# MSS_VIM register map
Vendor: Texas Instruments
Peripheral module from a debugger description file (folder radar).
Registers are 32-bit, read-write, no defined reset value unless marked. A register's access mark holds for its fields unless they carry their own. Offsets are as the file gives them; lines under a group give offsets from that group; [hi:lo] are bit positions; {n}, {i} and the like mark numbered series; 'fields as' and 'values as' point back to an identical list; <NAME> marks a mode.

## VIM
0x00 IRQIVEC
  [7:0] IRQIVEC — IRQIVEC Index vector. User and privilege mode read: The least significant bits represent the index of the IRQ pending interrupt with the highest precedence. When no interrupts are pending, IRQIVEC field will read 0x00. User and privilege mode write: Writes have no effect. User and privilege mode read: Clears the internal PULSE_HOLD flag corresponding to the vector number that is read out. Refer to Figure 1–9. for details about PULSE_HOLD flag which allows the module support both pulse and level type of interrupt inputs.
0x04 FIQIVEC
  [7:0] FIQIVEC — FIQIVEC Index vector. User and privilege mode read: The least significant bits represent the index of the FIQ pending interrupt with the highest precedence. When no interrupts are pending, FIQIVEC will read 0x00. User and privilege mode write: Writes have no effect. User and privilege mode read: Clears the internal PULSE_HOLD flag corresponding to the vector number that is read out. Refer to Figure 1–9. for details about PULSE_HOLD flag which allows the module support both pulse and level type of interrupt inputs.
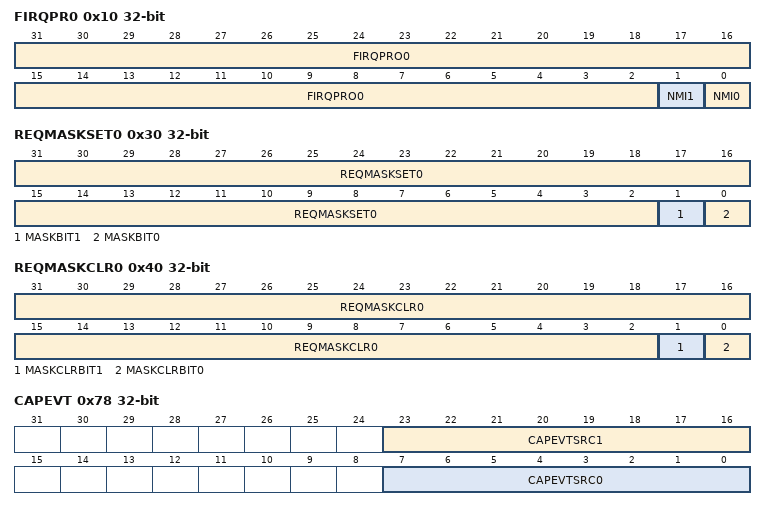
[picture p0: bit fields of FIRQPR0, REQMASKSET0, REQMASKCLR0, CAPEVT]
0x10 FIRQPR0 access per field
  [31:2] FIRQPRO0 rw — These bits determine whether an interrupt request from a peripheral is of type FIQ or IRQ. Each bit corresponds to one request channel between 0 and 31.
  [1] NMI1 ro — FIRQPR(0) and FIRQPR(1) bits are read-only and read ‘1’ always if NMI_DISABLE = 0. This ensures that lowest two channels are a fixed as NMI channels (no enabling is required).
  [0] NMI0 ro — FIRQPR(0) and FIRQPR(1) bits are read-only and read ‘1’ always if NMI_DISABLE = 0. This ensures that lowest two channels are a fixed as NMI channels (no enabling is required).
{0x10+4i} FIRQPR{i} (i=1..3)
  [31:0] FIRQPRO{i} — These bits determine whether an interrupt request from a peripheral is of type FIQ or IRQ. Each bit corresponds to one request channel between {32i} and {32i+31}.
{0x20+4i} INTREQ{i} (i=0..2)
  [31:0] INTREQ{i} — Determine whether an interrupt request is pending for the request channel between {32i} and {32i+31}. The interrupt mask register does not affect the value of the interrupt pending bit. INTREQ{i} [0] = Request channel {32i} ... INTREQ{i} [31] = Request channel {32i+31} User and privilege mode read: 0 = No interrupt event has occurred. 1 = Interrupt is pending. User mode write: Writes have no effect. Privilege mode write: 1 = Clears the pulse interrupt holding flag (PULSE_HOLD).
0x2C INTREQ3
  [31:0] INTREQ3 — Determine whether an interrupt request is pending for the request channel between 96 and 127. The interrupt mask register does not affect the value of the interrupt pending bit. INTREQ0 [0] = Request channel 96 ... INTREQ0 [31] = Request channel 127 User and privilege mode read: 0 = No interrupt event has occurred. 1 = Interrupt is pending. User mode write: Writes have no effect. Privilege mode write: 1 = Clears the pulse interrupt holding flag (PULSE_HOLD).
0x30 REQMASKSET0 access per field
  [31:2] REQMASKSET0 rw — REQMASKSET0 [31:0] Request mask set bits. This vector determines whether the interrupt request channel is enabled. REQMASKSET0 [0] = Request channel 0 ... REQMASKSET0 [31] = Request channel 31 User and privilege mode read: 0 = Interrupt request channel is disabled. 1 = Interrupt request channel is enabled. Privilege mode write: 0 = no effect 1 = Interrupt request channel is enabled.
  [1] MASKBIT1 ro — Default enabling of channels 1 and 0 REQMASKSET0(0) and REQMASKSET0(1) bits are read-only and read ‘1’ always if NMI_DISABLE = 0. This ensures that lowest two channels are a fixed as NMI channels (no enabling is required).
  [0] MASKBIT0 ro — Default enabling of channels 1 and 0 REQMASKSET0(0) and REQMASKSET0(1) bits are read-only and read ‘1’ always if NMI_DISABLE = 0. This ensures that lowest two channels are a fixed as NMI channels (no enabling is required).
{0x30+4i} REQMASKSET{i} (i=1..3)
  [31:0] REQMASKSET{i} — REQMASKSET{i} [31:0] Request mask set bits. This vector determines whether the interrupt request channel is enabled. REQMASKSET{i} [0] = Request channel {32i} ... REQMASKSET{i} [31] = Request channel {32i+31} User and privilege mode read: 0 = Interrupt request channel is disabled. 1 = Interrupt request channel is enabled. Privilege mode write: 0 = no effect 1 = Interrupt request channel is enabled.
0x40 REQMASKCLR0 access per field
  [31:2] REQMASKCLR0 rw — REQMASKCLR0 [31:0] Request mask set bits. This vector determines whether the interrupt request channel is enabled. REQMASKCLR0 [0] = Request channel 0 ... REQMASKCLR0 [31] = Request channel 31 User and privilege mode read: 0 = Interrupt request channel is disabled. 1 = Interrupt request channel is enabled. Privilege mode write: 0 = no effect 1 = Interrupt request channel is enabled.
  [1] MASKCLRBIT1 ro — Default enabling of channels 1 and 0 REQMASKCLR0(0) and REQMASKCLR0(1) bits are read-only and read ‘1’ always if NMI_DISABLE = 0. This ensures that lowest two channels are a fixed as NMI channels (no enabling is required).
  [0] MASKCLRBIT0 ro — Default enabling of channels 1 and 0 REQMASKCLR0(0) and REQMASKCLR0(1) bits are read-only and read ‘1’ always if NMI_DISABLE = 0. This ensures that lowest two channels are a fixed as NMI channels (no enabling is required).
{0x40+4i} REQMASKCLR{i} (i=1..3)
  [31:0] REQMASKCLR{i} — REQMASKCLR{i} [31:0] Request mask set bits. This vector determines whether the interrupt request channel is enabled. REQMASKCLR{i} [0] = Request channel {32i} ... REQMASKCLR{i} [31] = Request channel {32i+31} User and privilege mode read: 0 = Interrupt request channel is disabled. 1 = Interrupt request channel is enabled. Privilege mode write: 0 = no effect 1 = Interrupt request channel is enabled.
{0x50+4i} WAKEMASKSET{i} (i=0..3)
  [31:0] WAKEMASKSET{i} — WAKEMASKSET{i} [31:0] Wake-up mask set bits. This vector determines whether the wake-up interrupt line is enabled. WAKEMASKSET{i} [0] = Wake-up interrupt line {32i} ... WAKEMASKSET{i} [31] = Wake-up interrupt line {32i+31} User and privilege mode read: 0 = Wake-up interrupt line is disabled. 1 = Wake-up interrupt line is enabled. Privilege mode write: 0 = no effect 1 = Wake-up interrupt line is enabled.
{0x60+4i} WAKEMASKCLR{i} (i=0..3)
  [31:0] WAKEMASKCLR{i} — WAKEMASKCLR{i} [31:0] Wake-up mask CLR bits. This vector determines whether the wake-up interrupt line is enabled. WAKEMASKCLR{i} [0] = Wake-up interrupt line {32i} ... WAKEMASKCLR{i} [31] = Wake-up interrupt line {32i+31} User and privilege mode read: 0 = Wake-up interrupt line is disabled. 1 = Wake-up interrupt line is enabled. Privilege mode write: 0 = no effect 1 = Wake-up interrupt line is enabled.
0x70 IRQVECREG ro
  [31:0] IRQVECREG — IRQVECREG [31:0] IRQ Interrupt vector register. This vector gives the address of the ISR with the highest pending IRQ request. The CPU reads the address and branches to this location. User and privilege mode read: The address of the interrupt service routine of the highest priority pending IRQ request. User and privilege mode write: Writes have no effect. User and privilege mode read: Clears the internal PULSE_HOLD flag for vector number corresponding to the VECTOR ADDRESS that is read out. Refer to Figure 1–9. for details about PULSE_HOLD flag which allows the module support both pulse and level type of interrupt inputs.
0x74 FIQVECREG ro
  [31:0] FIQVECREG — FIQVECREG [31:0] FIQ Interrupt vector register. This vector gives the address of the ISR with the highest pending FIQ request. The CPU reads the address and branches to this location. User and privilege mode read: The address of the interrupt service routine of the highest priority pending FIQ request. User and privilege mode write: Writes have no effect. User and privilege mode read: Clears the internal PULSE_HOLD flag for vector number corresponding to the VECTOR ADDRESS that is read out. Refer to Figure 1–9. for details about PULSE_HOLD flag which allows the module support both pulse and level type of interrupt inputs.
0x78 CAPEVT
  [23:16] CAPEVTSRC1 — CAPEVTSRC1. Capture event source 1 mapping control. These bits determine which interrupt request maps to the capture event source 1 of the RTI: User and privilege mode read: 00000000 Interrupt Request 0. 00000001 Interrupt Request 1 ... ... 11111111 Interrupt Request 255. Privilege mode write: Set the interrupt request line to be forwarded to the RTI.
  [7:0] CAPEVTSRC0 — CAPEVTSRC0. Capture event source 0 mapping control. These bits determine which interrupt request maps to the capture event source 0 of the RTI: User and privilege mode read: 00000000 Interrupt Request 0 00000001 Interrupt Request 1 ... ... 11111111 Interrupt Request 255 Privilege mode write: Set the interrupt request line to be forwarded to the RTI.
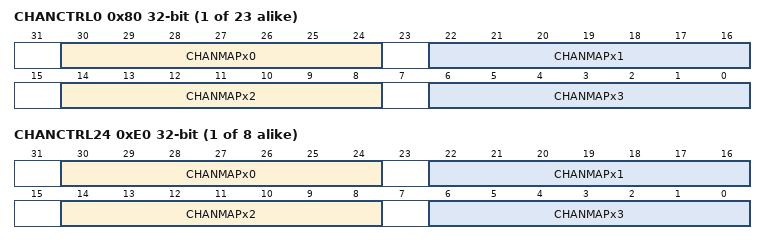
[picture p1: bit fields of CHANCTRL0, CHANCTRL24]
{0x80+4i} CHANCTRL{i} (i=0..22)
  [30:24] CHANMAPx0 — CHANMAPx0. Interrupt CHANx0 mapping control. These bits determine which interrupt request the priority channel CHANx0 maps to: User and privilege mode read: 0000000 Interrupt Request 0 maps to Channel priority CHANx0 0000001 Interrupt Request 1 maps to Channel priority CHANx0 ... ... 1111111 Interrupt Request 127 maps to Channel priority CHANx0 Privilege mode write: Set the Channel priority CHANx0 with the interrupt request.
  [22:16] CHANMAPx1 — CHANMAPx1. Interrupt CHANx1 mapping control. These bits determine which interrupt request the priority channel CHANx1 maps to: User and privilege mode read: 0000000 Interrupt Request 0 maps to Channel priority CHANx1. 0000001 Interrupt Request 1 maps to Channel priority CHANx1. ... ... 1111111 Interrupt Request 127 maps to Channel priority CHANx1. Privilege mode write: Set the Channel priority CHANx1 with the interrupt request.
  [14:8] CHANMAPx2 — CHANMAPx2. Interrupt CHANx2 mapping control. These bits determine which interrupt request the priority channel CHANx2 maps to: User and privilege mode read: 0000000 Interrupt Request 0 maps to Channel priority CHANx2 0000001 Interrupt Request 1 maps to Channel priority CHANx2 ... ... 1111111 Interrupt Request 127 maps to Channel priority CHANx2 Privilege mode write: Set the Channel priority CHANx2 with the interrupt request.
  [6:0] CHANMAPx3 — CHANMAPx3. Interrupt CHANx3 mapping control. These bits determine which interrupt request the priority channel CHANx3 maps to: User and privilege mode read: 0000000 Interrupt Request 0 maps to Channel priority CHANx3 0000001 Interrupt Request 1 maps to Channel priority CHANx3 ... ... 1111111 Interrupt Request 127 maps to Channel priority CHANx3 Privilege mode write: Set the Channel priority CHANx3 with the interrupt request.
0xDC CHANCTRL23 access not given
{0x80+4i} CHANCTRL{i} (i=24..31)
  fields as CHANCTRL0
